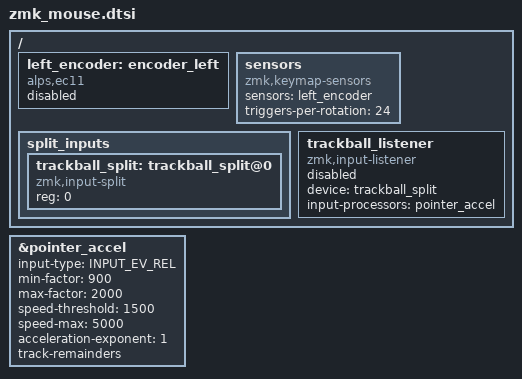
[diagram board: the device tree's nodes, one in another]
/ {
    left_encoder: encoder_left {
        compatible = "alps,ec11";
        status = "disabled";
    };

    sensors: sensors {
        compatible = "zmk,keymap-sensors";
        sensors = <&left_encoder>;
        triggers-per-rotation = <24>;
    };
    
    split_inputs {
        #address-cells = <1>;
        #size-cells = <0>;

        trackball_split: trackball_split@0 {
            compatible = "zmk,input-split";
            reg = <0>;
        };
    };

    trackball_listener: trackball_listener {
        compatible = "zmk,input-listener";
        status = "disabled";
        device = <&trackball_split>;
        input-processors = <
            &pointer_accel      // Acceleration processor
        >;
    };
};

&pointer_accel {
    input-type = <INPUT_EV_REL>;
    min-factor = <900>;        // 0.9x minimum
    max-factor = <2000>;       // 2.0x maximum
    speed-threshold = <1500>;  // Start accelerating later
    speed-max = <5000>;         // 6000 counts/sec for max accel
    acceleration-exponent = <1>; // Linear acceleration
    track-remainders;          // Track fractional movements
};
